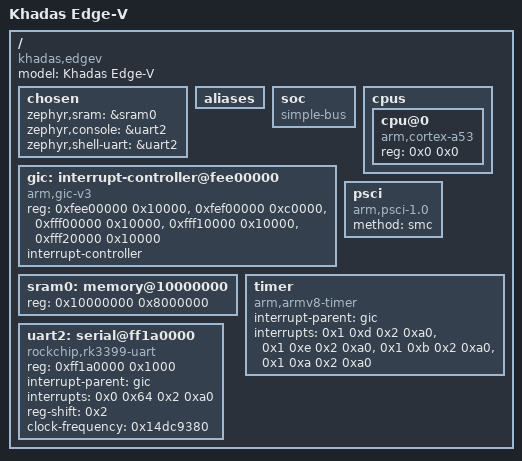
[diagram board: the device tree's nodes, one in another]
/dts-v1/;

/* node '/' defined in zephyr/dts/common/skeleton.dtsi:9 */
/ {
	#address-cells = < 0x1 >;    /* in zephyr/dts/arm64/rockchip/rk3399.dtsi:12 */
	#size-cells = < 0x1 >;       /* in zephyr/dts/arm64/rockchip/rk3399.dtsi:13 */
	model = "Khadas Edge-V";     /* in zephyr/boards/khadas/edgev/khadas_edgev.dts:12 */
	compatible = "khadas,edgev"; /* in zephyr/boards/khadas/edgev/khadas_edgev.dts:13 */

	/* node '/chosen' defined in zephyr/dts/common/skeleton.dtsi:13 */
	chosen {
		zephyr,sram = &sram0;       /* in zephyr/boards/khadas/edgev/khadas_edgev.dts:16 */
		zephyr,console = &uart2;    /* in zephyr/boards/khadas/edgev/khadas_edgev.dts:17 */
		zephyr,shell-uart = &uart2; /* in zephyr/boards/khadas/edgev/khadas_edgev.dts:18 */
	};

	/* node '/aliases' defined in zephyr/dts/common/skeleton.dtsi:15 */
	aliases {
	};

	/* node '/soc' defined in zephyr/dts/arm64/armv8-a.dtsi:10 */
	soc {
		#address-cells = < 0x1 >;  /* in zephyr/dts/arm64/armv8-a.dtsi:11 */
		#size-cells = < 0x1 >;     /* in zephyr/dts/arm64/armv8-a.dtsi:12 */
		compatible = "simple-bus"; /* in zephyr/dts/arm64/armv8-a.dtsi:13 */
		ranges;                    /* in zephyr/dts/arm64/armv8-a.dtsi:14 */
	};

	/* node '/cpus' defined in zephyr/dts/arm64/rockchip/rk3399.dtsi:15 */
	cpus {
		#address-cells = < 0x2 >; /* in zephyr/dts/arm64/rockchip/rk3399.dtsi:16 */
		#size-cells = < 0x0 >;    /* in zephyr/dts/arm64/rockchip/rk3399.dtsi:17 */

		/* node '/cpus/cpu@0' defined in zephyr/dts/arm64/rockchip/rk3399.dtsi:19 */
		cpu@0 {
			device_type = "cpu";           /* in zephyr/dts/arm64/rockchip/rk3399.dtsi:20 */
			compatible = "arm,cortex-a53"; /* in zephyr/dts/arm64/rockchip/rk3399.dtsi:21 */
			reg = < 0x0 0x0 >;             /* in zephyr/dts/arm64/rockchip/rk3399.dtsi:22 */
		};
	};

	/* node '/interrupt-controller@fee00000' defined in zephyr/dts/arm64/rockchip/rk3399.dtsi:56 */
	gic: interrupt-controller@fee00000 {
		#address-cells = < 0x1 >;     /* in zephyr/dts/arm64/rockchip/rk3399.dtsi:57 */
		compatible = "arm,gic-v3",
		             "arm,gic";       /* in zephyr/dts/arm64/rockchip/rk3399.dtsi:58 */
		reg = < 0xfee00000 0x10000 >,
		      < 0xfef00000 0xc0000 >,
		      < 0xfff00000 0x10000 >,
		      < 0xfff10000 0x10000 >,
		      < 0xfff20000 0x10000 >; /* in zephyr/dts/arm64/rockchip/rk3399.dtsi:59 */
		interrupt-controller;         /* in zephyr/dts/arm64/rockchip/rk3399.dtsi:64 */
		#interrupt-cells = < 0x4 >;   /* in zephyr/dts/arm64/rockchip/rk3399.dtsi:65 */
		status = "okay";              /* in zephyr/dts/arm64/rockchip/rk3399.dtsi:66 */
		phandle = < 0x1 >;            /* in zephyr/dts/arm64/rockchip/rk3399.dtsi:80 */
	};

	/* node '/psci' defined in zephyr/dts/arm64/rockchip/rk3399.dtsi:69 */
	psci: psci {
		compatible = "arm,psci-1.0"; /* in zephyr/dts/arm64/rockchip/rk3399.dtsi:70 */
		method = "smc";              /* in zephyr/dts/arm64/rockchip/rk3399.dtsi:71 */
	};

	/* node '/memory@10000000' defined in zephyr/dts/arm64/rockchip/rk3399.dtsi:74 */
	sram0: memory@10000000 {
		reg = < 0x10000000 0x8000000 >; /* in zephyr/dts/arm64/rockchip/rk3399.dtsi:75 */
	};

	/* node '/timer' defined in zephyr/dts/arm64/rockchip/rk3399.dtsi:78 */
	timer {
		compatible = "arm,armv8-timer";    /* in zephyr/dts/arm64/rockchip/rk3399.dtsi:79 */
		interrupt-parent = < &gic >;       /* in zephyr/dts/arm64/rockchip/rk3399.dtsi:80 */
		interrupts = < 0x1 0xd 0x2 0xa0 >,
		             < 0x1 0xe 0x2 0xa0 >,
		             < 0x1 0xb 0x2 0xa0 >,
		             < 0x1 0xa 0x2 0xa0 >; /* in zephyr/dts/arm64/rockchip/rk3399.dtsi:81 */
	};

	/* node '/serial@ff1a0000' defined in zephyr/dts/arm64/rockchip/rk3399.dtsi:91 */
	uart2: serial@ff1a0000 {
		compatible = "rockchip,rk3399-uart",
		             "ns16550";              /* in zephyr/dts/arm64/rockchip/rk3399.dtsi:92 */
		reg = < 0xff1a0000 0x1000 >;         /* in zephyr/dts/arm64/rockchip/rk3399.dtsi:93 */
		interrupt-parent = < &gic >;         /* in zephyr/dts/arm64/rockchip/rk3399.dtsi:94 */
		interrupts = < 0x0 0x64 0x2 0xa0 >;  /* in zephyr/dts/arm64/rockchip/rk3399.dtsi:95 */
		reg-shift = < 0x2 >;                 /* in zephyr/dts/arm64/rockchip/rk3399.dtsi:97 */
		clock-frequency = < 0x14dc9380 >;    /* in zephyr/dts/arm64/rockchip/rk3399.dtsi:98 */
		status = "okay";                     /* in zephyr/boards/khadas/edgev/khadas_edgev.dts:31 */
	};
};
